# R7FA6E10F register map
Vendor: Renesas Electronics Corporation; Series: RA6; File version: 1.20.00
CPU: CM33 r0p4, little endian, MPU, FPU, VTOR, 4 interrupt priority bits, 96 interrupts
Registers are 8-bit, read-write, reset 0x0 unless marked. A register's access mark holds for its fields unless they carry their own. Offsets are from the block's base; [hi:lo] are bit positions; {n}, {i} and the like mark numbered series; 'fields as' and 'values as' point back to an identical list.

## SCI0 — Serial Communication Interface
Base 0x40118000
Same registers: SCI9 0x40118900
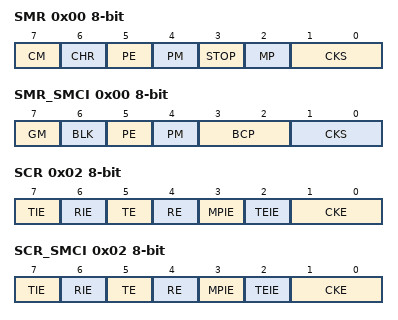
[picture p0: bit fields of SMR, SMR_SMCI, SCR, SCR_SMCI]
0x00 SMR — Serial Mode Register for Non,Smart Card Interface Mode (SCMR.SMIF = 0)
  [7] CM — Communication Mode
  [6] CHR — Character Length
  [5] PE — Parity Enable
  [4] PM — Parity Mode
  [3] STOP — Stop Bit Length
  [2] MP — Multi,Processor Mode
  [1:0] CKS — Clock Select
0x00 SMR_SMCI (alternate view of SMR) — Serial Mode Register for Smart Card Interface Mode (SCMR.SMIF = 1)
  [7] GM — GSM Mode
  [6] BLK — Block Transfer Mode
  [5] PE — Parity Enable
  [4] PM — Parity Mode
  [3:2] BCP — Base Clock Pulse
  [1:0] CKS — Clock Select
0x01 BRR reset 0xFF — Bit Rate Register
0x02 SCR — Serial Control Register for Non,Smart Card Interface Mode (SCMR.SMIF = 0)
  [7] TIE — Transmit Interrupt Enable
  [6] RIE — Receive Interrupt Enable
  [5] TE — Transmit Enable
  [4] RE — Receive Enable
  [3] MPIE — Multi,Processor Interrupt Enable
  [2] TEIE — Transmit End Interrupt Enable
  [1:0] CKE — Clock Enable
0x02 SCR_SMCI (alternate view of SCR) — Serial Control Register for Smart Card Interface Mode (SCMR.SMIF = 1)
  fields as SCR
0x03 TDR reset 0xFF — Transmit Data Register
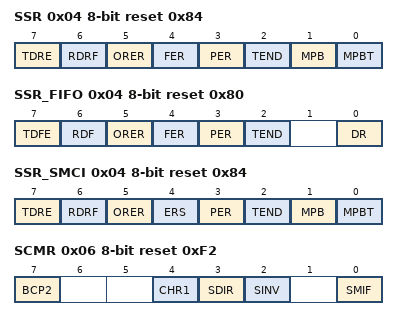
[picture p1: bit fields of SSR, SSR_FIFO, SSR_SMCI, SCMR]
0x04 SSR reset 0x84 — Serial Status Register for Non,Smart Card Interface and Non,FIFO Mode (SCMR.SMIF = 0, FCR.FM = 0, and MMR.MANEN = 0)
  [7] TDRE — Transmit Data Empty Flag
  [6] RDRF — Receive Data Full Flag
  [5] ORER — Overrun Error Flag
  [4] FER — Framing Error Flag
  [3] PER — Parity Error Flag
  [2] TEND ro — Transmit End Flag
  [1] MPB ro — Multi,Processor
  [0] MPBT — Multi,Processor Bit Transfer
0x04 SSR_FIFO reset 0x80 (alternate view of SSR) — Serial Status Register for Non,Smart Card Interface and FIFO Mode (SCMR.SMIF = 0, FCR.FM = 1, and MMR.MANEN = 0)
  [7] TDFE — Transmit FIFO Data Empty Flag
  [6] RDF — Receive FIFO Data Full Flag
  [5] ORER — Overrun Error Flag
  [4] FER — Framing Error Flag
  [3] PER — Parity Error Flag
  [2] TEND — Transmit End Flag
  [0] DR — Receive Data Ready Flag
0x04 SSR_SMCI reset 0x84 (alternate view of SSR) — Serial Status Register for Smart Card Interface Mode (SCMR.SMIF = 1, and MMR.MANEN = 0)
  [7] TDRE — Transmit Data Empty Flag
  [6] RDRF — Receive Data Full Flag
  [5] ORER — Overrun Error Flag
  [4] ERS — Error Signal Status Flag
  [3] PER — Parity Error Flag
  [2] TEND ro — Transmit End Flag
  [1] MPB ro — Multi,Processor
  [0] MPBT — Multi,Processor Bit Transfer
0x05 RDR ro — Receive Data Register
0x06 SCMR reset 0xF2 — Smart Card Mode Register
  [7] BCP2 — Base Clock Pulse 2
  [4] CHR1 — Character Length 1
  [3] SDIR — Transmitted/Received Data Transfer Direction
  [2] SINV — Transmitted/Received Data Invert
  [0] SMIF — Smart Card Interface Mode Select
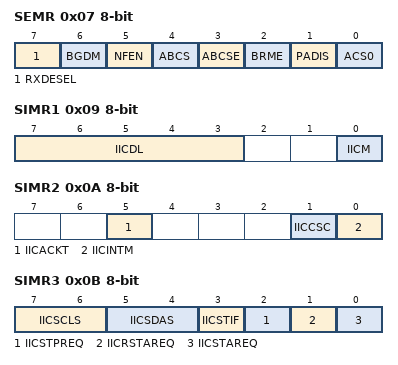
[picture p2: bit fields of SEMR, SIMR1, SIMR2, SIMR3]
0x07 SEMR — Serial Extended Mode Register
  [7] RXDESEL — Asynchronous Start Bit Edge Detection Select
  [6] BGDM — Baud Rate Generator Double,Speed Mode Select
  [5] NFEN — Digital Noise Filter Function Enable
  [4] ABCS — Asynchronous Mode Base Clock Select
  [3] ABCSE — Asynchronous Mode Extended Base Clock Select 1
  [2] BRME — Bit Rate Modulation Enable
  [1] PADIS — Preamble function Disable
  [0] ACS0 — Asynchronous Mode Clock Source Select
0x08 SNFR — Noise Filter Setting Register
  [2:0] NFCS — Noise Filter Clock Select
0x09 SIMR1 — IIC Mode Register 1
  [7:3] IICDL — SDAn Delay Output Select
  [0] IICM — Simple IIC Mode Select
0x0A SIMR2 — IIC Mode Register 2
  [5] IICACKT — ACK Transmission Data
  [1] IICCSC — Clock Synchronization
  [0] IICINTM — IIC Interrupt Mode Select
0x0B SIMR3 — IIC Mode Register 3
  [7:6] IICSCLS — SCLn Output Select
  [5:4] IICSDAS — SDAn Output Select
  [3] IICSTIF — Issuing of Start, Restart, or Stop Condition Completed Flag
  [2] IICSTPREQ — Stop Condition Generation
  [1] IICRSTAREQ — Restart Condition Generation
  [0] IICSTAREQ — Start Condition Generation
0x0C SISR ro — IIC Status Register
  [0] IICACKR — ACK Reception Data Flag
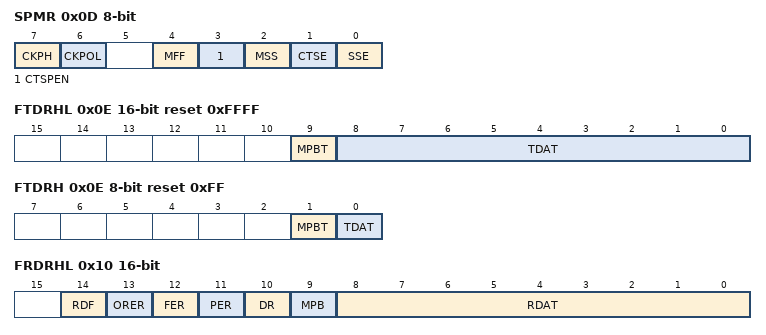
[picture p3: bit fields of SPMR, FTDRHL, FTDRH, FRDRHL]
0x0D SPMR — SPI Mode Register
  [7] CKPH — Clock Phase Select
  [6] CKPOL — Clock Polarity Select
  [4] MFF — Mode Fault Flag
  [3] CTSPEN — CTS external pin Enable
  [2] MSS — Master Slave Select
  [1] CTSE — CTS Enable
  [0] SSE — SSn Pin Function Enable
0x0E FTDRHL 16-bit wo reset 0xFFFF — Transmit FIFO Data Register
  [9] MPBT — Multi,Processor Transfer Bit Flag
  [8:0] TDAT — Serial transmit data
0x0E TDRHL 16-bit reset 0xFFFF (alternate view of FTDRHL) — Transmit Data Register for Non,Manchester mode (MMR.MANEN = 0)
  [8:0] TDAT — Serial Transmit Data
0x0E FTDRH wo reset 0xFF (alternate view of FTDRHL) — Transmit FIFO Data Register
  [1] MPBT — Multi,Processor Transfer Bit Flag
  [0] TDAT — Serial transmit data
0x0F FTDRL wo reset 0xFF (alternate view of FTDRHL) — Transmit FIFO Data Register
  [7:0] TDAT — Serial transmit data
0x10 FRDRHL 16-bit ro — Receive FIFO Data Register
  [14] RDF — Receive FIFO Data Full Flag
  [13] ORER — Overrun Error Flag
  [12] FER — Framing Error Flag
  [11] PER — Parity Error Flag
  [10] DR — Receive Data Ready Flag
  [9] MPB — Multi,Processor Bit Flag
  [8:0] RDAT — Serial receive data
0x10 RDRHL 16-bit ro (alternate view of FRDRHL) — Receive Data Register for Non,Manchester mode (MMR.MANEN = 0)
  [8:0] RDAT — Serial Receive Data
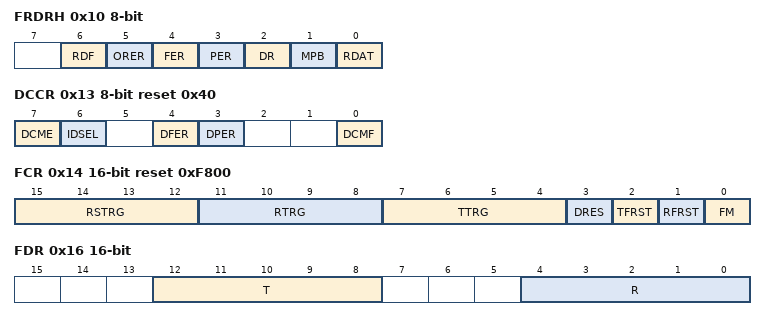
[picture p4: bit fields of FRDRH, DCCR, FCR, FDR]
0x10 FRDRH ro (alternate view of FRDRHL) — Receive FIFO Data Register
  [6] RDF — Receive FIFO Data Full Flag
  [5] ORER — Overrun Error Flag
  [4] FER — Framing Error Flag
  [3] PER — Parity Error Flag
  [2] DR — Receive Data Ready Flag
  [1] MPB — Multi,Processor Bit Flag
  [0] RDAT — Serial receive data
0x11 FRDRL ro (alternate view of FRDRHL) — Receive FIFO Data Register
  [7:0] RDAT — Serial receive data
0x12 MDDR reset 0xFF — Modulation Duty Register
0x13 DCCR reset 0x40 — Data Compare Match Control Register
  [7] DCME — Data Compare Match Enable
  [6] IDSEL — ID Frame Select
  [4] DFER — Data Compare Match Framing Error Flag
  [3] DPER — Data Compare Match Parity Error Flag
  [0] DCMF — Data Compare Match Flag
0x14 FCR 16-bit reset 0xF800 — FIFO Control Register
  [15:12] RSTRG — RTS Output Active Trigger Number Select
  [11:8] RTRG — Receive FIFO Data Trigger Number
  [7:4] TTRG — Transmit FIFO Data Trigger Number
  [3] DRES — Receive Data Ready Error Select
  [2] TFRST — Transmit FIFO Data Register Reset
  [1] RFRST — Receive FIFO Data Register Reset
  [0] FM — FIFO Mode Select
0x16 FDR 16-bit ro — FIFO Data Count Register
  [12:8] T — Transmit FIFO Data Count
  [4:0] R — Receive FIFO Data Count
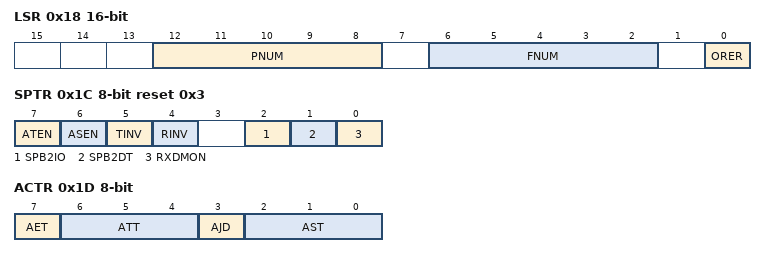
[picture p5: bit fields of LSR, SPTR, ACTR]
0x18 LSR 16-bit ro — Line Status Register
  [12:8] PNUM — Parity Error Count
  [6:2] FNUM — Framing Error Count
  [0] ORER — Overrun Error Flag
0x1A CDR 16-bit — Compare Match Data Register
  [8:0] CMPD — Compare Match Data
0x1C SPTR reset 0x3 — Serial Port Register
  [7] ATEN — Adjust transmit timing enable
  [6] ASEN — Adjust receive sampling timing enable
  [5] TINV — TXD invert bit
  [4] RINV — RXD invert bit
  [2] SPB2IO — Serial Port Break I/O
  [1] SPB2DT — Serial Port Break Data Select
  [0] RXDMON ro — Serial Input Data Monitor
0x1D ACTR — Adjustment Communication Timing Register
  [7] AET — Adjustment edge for transmit timing
  [6:4] ATT — Adjustment value for Transmit timing
  [3] AJD — Adjustment Direction for receive sampling timing
  [2:0] AST — Adjustment value for receive Sampling Timing

## SCI1 — Serial Communication Interface 1
Base 0x40118100
Registers as SCI0, without SEMR; these are added or differ:
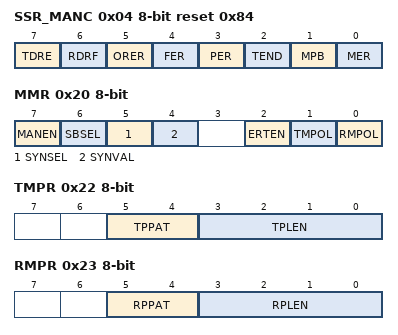
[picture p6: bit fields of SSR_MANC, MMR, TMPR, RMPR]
0x04 SSR_MANC reset 0x84 (alternate view of SSR) — Serial Status Register for Manchester Mode (SCMR.SMIF = 0, and MMR.MANEN = 1)
  [7] TDRE — Transmit Data Empty Flag
  [6] RDRF — Receive Data Full Flag
  [5] ORER — Overrun Error Flag
  [4] FER — Framing Error Flag
  [3] PER — Parity Error Flag
  [2] TEND ro — Transmit End Flag
  [1] MPB ro — Multi,Processor
  [0] MER — Manchester Error Flag
0x20 MMR (alternate view of ESMER) — Manchester Mode Register
  [7] MANEN — Manchester Mode Enable
  [6] SBSEL — Start Bit Select
  [5] SYNSEL — SYNC Select
  [4] SYNVAL — SYNC value Setting
  [2] ERTEN — Manchester Edge Retiming Enable
  [1] TMPOL — Polarity of Transmit Manchester Code
  [0] RMPOL — Polarity of Received Manchester Code
0x22 TMPR (alternate view of CR1) — Transmit Manchester Preface Setting Register
  [5:4] TPPAT — Transmit preface pattern
  [3:0] TPLEN — Transmit preface length
0x23 RMPR (alternate view of CR2) — Receive Manchester Preface Setting Register
  [5:4] RPPAT — Receive Preface Pattern
  [3:0] RPLEN — Receive Preface Length
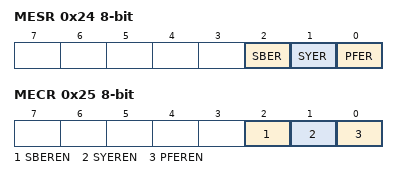
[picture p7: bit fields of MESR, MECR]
0x24 MESR (alternate view of CR3) — Manchester Extended Error Status Register
  [2] SBER — Start Bit Error flag
  [1] SYER — SYNC Error flag
  [0] PFER — Preface Error flag
0x25 MECR — Manchester Extended Error Control Register
  [2] SBEREN — Start Bit Error Enable
  [1] SYEREN — Receive SYNC Error Enable
  [0] PFEREN — Preface Error Enable

## SCI2 — Serial Communication Interface 2
Base 0x40118200
Registers as SCI1; these are added or differ:
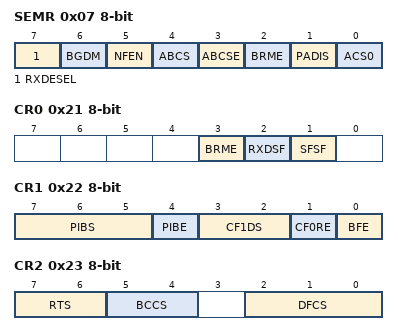
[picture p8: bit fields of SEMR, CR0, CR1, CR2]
0x07 SEMR — Serial Extended Mode Register
  fields as SCI0.SEMR
0x20 ESMER — Extended Serial Module Enable Register
  [0] ESME — Extended Serial Mode Enable
0x21 CR0 — Control Register 0
  [3] BRME — Bit Rate Measurement Enable
  [2] RXDSF ro — RXDXn Input Status Flag
  [1] SFSF ro — Start Frame Status Flag
0x22 CR1 — Control Register 1
  [7:5] PIBS — Priority Interrupt Bit Select
  [4] PIBE — Priority Interrupt Bit Enable
  [3:2] CF1DS — Control Field 1 Data Register Select
  [1] CF0RE — Control Field 0 Reception Enable
  [0] BFE — Break Field Enable
0x23 CR2 — Control Register 2
  [7:6] RTS — RXDXn Reception Sampling Timing Select
  [5:4] BCCS — Bus Collision Detection Clock Select
  [2:0] DFCS — RXDXn Signal Digital Filter Clock Select
0x24 CR3 — Control Register 3
  [0] SDST — Start Frame Detection Start
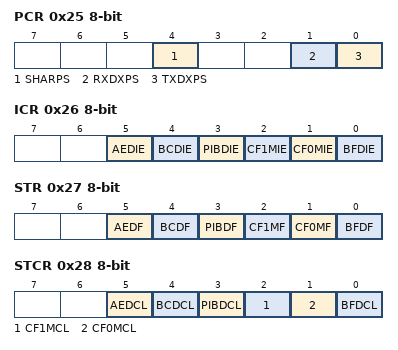
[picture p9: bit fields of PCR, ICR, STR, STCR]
0x25 PCR (alternate view of MECR) — Port Control Register
  [4] SHARPS — TXDXn/RXDXn Pin Multiplexing Select
  [1] RXDXPS — RXDXn Signal Polarity Select
  [0] TXDXPS — TXDXn Signal Polarity Select
0x26 ICR — Interrupt Control Register
  [5] AEDIE — Valid Edge Detected Interrupt Enable
  [4] BCDIE — Bus Collision Detected Interrupt Enable
  [3] PIBDIE — Priority Interrupt Bit Detected Interrupt Enable
  [2] CF1MIE — Control Field 1 Match Detected Interrupt Enable
  [1] CF0MIE — Control Field 0 Match Detected Interrupt Enable
  [0] BFDIE — Break Field Low Width Detected Interrupt Enable
0x27 STR ro — Status Register
  [5] AEDF — Valid Edge Detection Flag
  [4] BCDF — Bus Collision Detected Flag
  [3] PIBDF — Priority Interrupt Bit Detection Flag
  [2] CF1MF — Control Field 1 Match Flag
  [1] CF0MF — Control Field 0 Match Flag
  [0] BFDF — Break Field Low Width Detection Flag
0x28 STCR — Status Clear Register
  [5] AEDCL — AEDF Clear
  [4] BCDCL — BCDF Clear
  [3] PIBDCL — PIBDF Clear
  [2] CF1MCL — CF1MF Clear
  [1] CF0MCL — CF0MF Clear
  [0] BFDCL — BFDF Clear
0x29 CF0DR — Control Field 0 Data Register
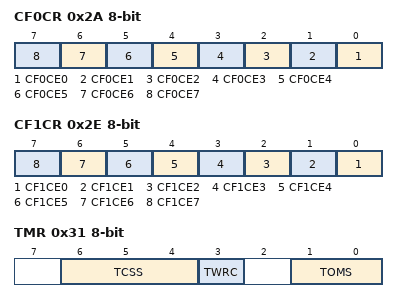
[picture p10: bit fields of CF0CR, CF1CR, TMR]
0x2A CF0CR — Control Field 0 Compare Enable Register
  [n] CF0CE{n} (n=0..7) — Control Field {n} Bit 0 Compare Enable
0x2B CF0RR — Control Field 0 Receive Data Register
0x2C PCF1DR — Primary Control Field 1 Data Register
0x2D SCF1DR — Secondary Control Field 1 Data Register
0x2E CF1CR — Control Field 1 Compare Enable Register
  [n] CF1CE{n} (n=0..7) — Control Field 1 Bit {n} Compare Enable
0x2F CF1RR — Control Field 1 Receive Data Register
0x30 TCR — Timer Control Register
  [0] TCST — Timer Count Start
0x31 TMR — Timer Mode Register
  [6:4] TCSS — Timer Count Clock Source Select
  [3] TWRC — Counter Write Control
  [1:0] TOMS — Timer Operating Mode Select
0x32 TPRE reset 0xFF — Timer Prescaler Register
0x33 TCNT reset 0xFF — Timer Count Register

## SCI3 — Serial Communication Interface
Base 0x40118300
Same registers: SCI4 0x40118400
Registers as SCI2, without ESMER, CR{n} (n=0..3), PCR, ICR, STR, STCR, CF0DR, CF0CR, CF0RR, PCF1DR, SCF1DR, CF1CR, CF1RR, TCR, TMR, TPRE, TCNT; these are added or differ:
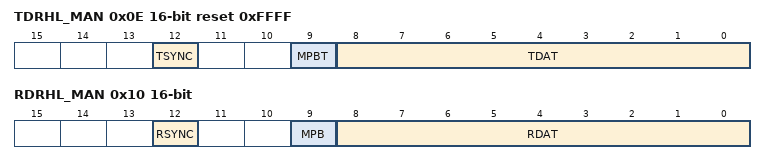
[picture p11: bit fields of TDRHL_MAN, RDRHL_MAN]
0x0E TDRHL_MAN 16-bit reset 0xFFFF (alternate view of FTDRHL) — Transmit Data Register for Manchester mode (MMR.MANEN = 1)
  [12] TSYNC — Transmit SYNC data bit
  [9] MPBT — Multi,processor transfer bit flag
  [8:0] TDAT — Serial transmit data
0x10 RDRHL_MAN 16-bit ro (alternate view of FRDRHL) — Receive Data Register for Manchester mode (MMR.MANEN = 1)
  [12] RSYNC — Receive SYNC data bit
  [9] MPB — Multi,processor bit
  [8:0] RDAT — Serial receive data
